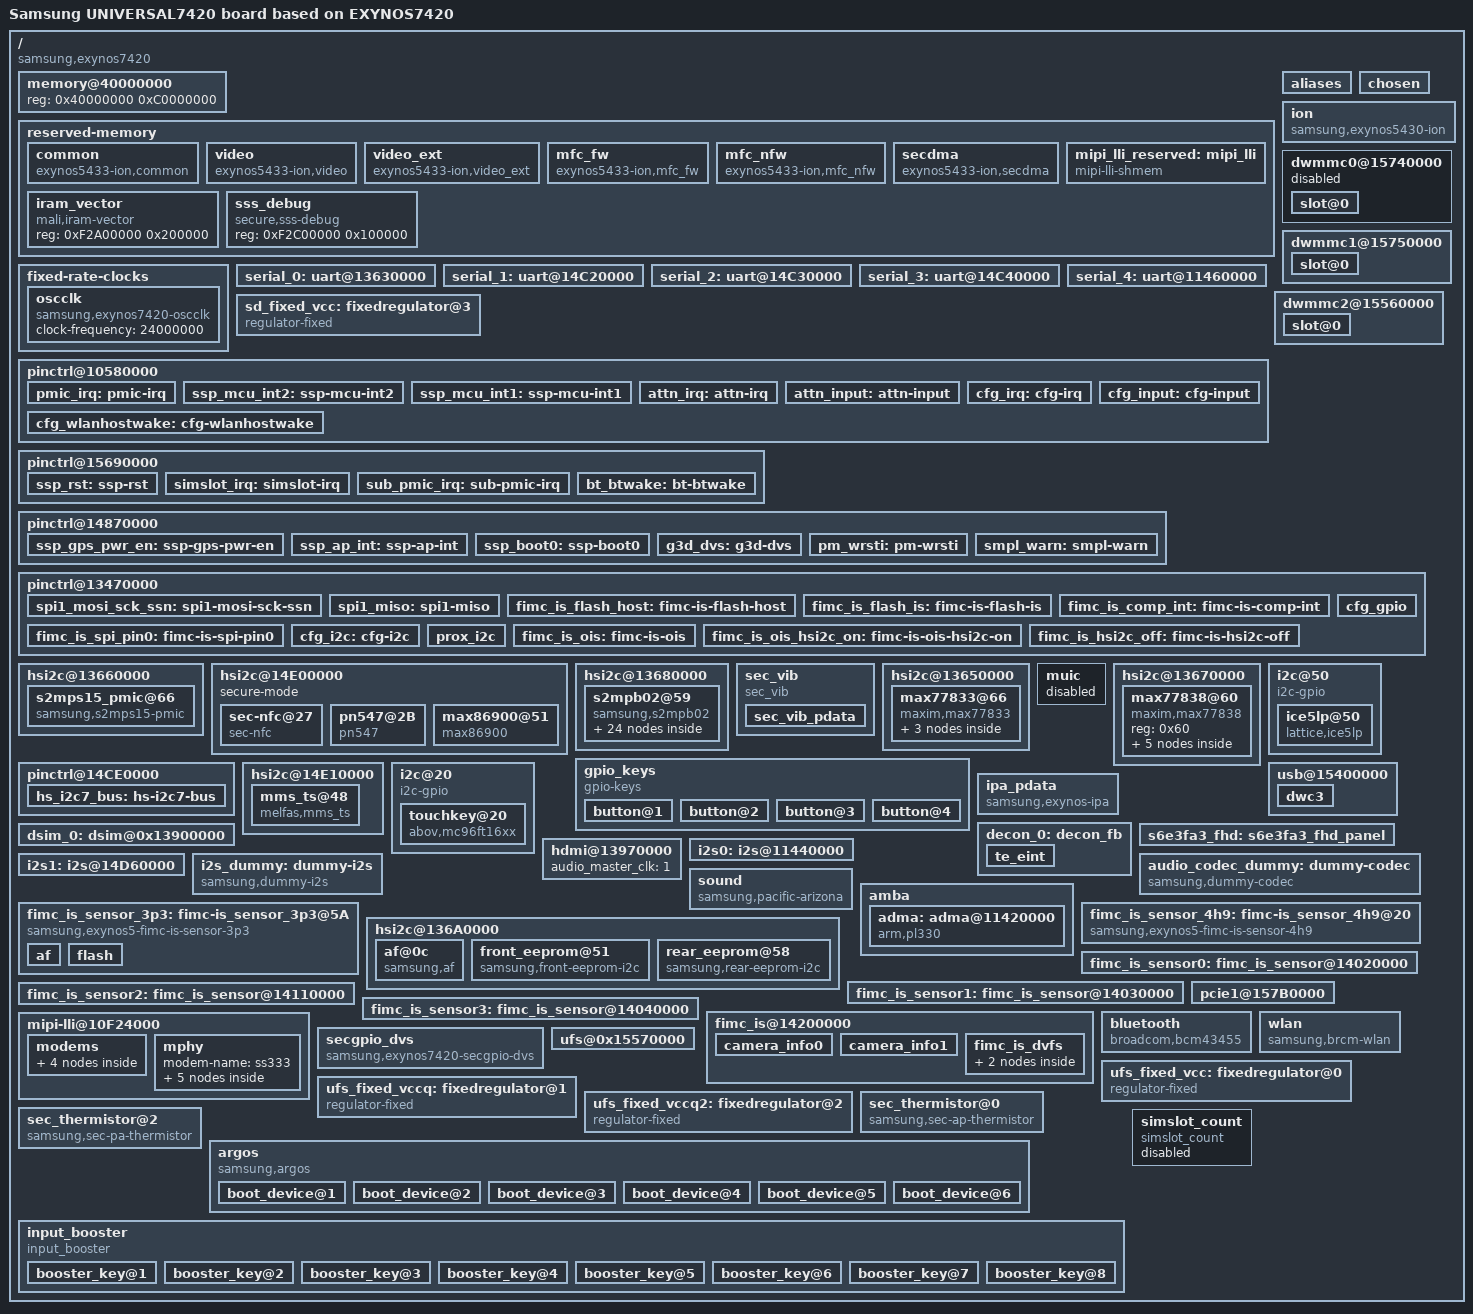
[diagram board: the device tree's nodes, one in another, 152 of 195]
/*
 * SAMSUNG UNIVERSAL7420 board device tree source
 *
 * Copyright (c) 2014 Samsung Electronics Co., Ltd.
 *		http://www.samsung.com
 *
 * This program is free software; you can redistribute it and/or modify
 * it under the terms of the GNU General Public License version 2 as
 * published by the Free Software Foundation.
*/

#include "exynos7420.dtsi"

/ {
	model = "Samsung UNIVERSAL7420 board based on EXYNOS7420";
	compatible = "samsung,exynos7420", "samsung,UNIVERSAL7420";

	memory@40000000 {
		device_type = "memory";
		reg = <0x40000000 0xC0000000>;
	};

	reserved-memory {
		#address-cells = <1>;
		#size-cells = <1>;
		ranges;

		common {
			compatible = "exynos5433-ion,common";
			size = <0x600000>;
			alignment = <0x1000>;
			id = <0>;
		};

		video {
			compatible = "exynos5433-ion,video";
			secure;
			reg = <0xE2A00000 0xE400000>;
			id = <11>;
			compat-id = <4 5 6 7>;
		};

		video_ext {
			compatible = "exynos5433-ion,video_ext";
			secure;
			reg = <0xF0E00000 0x600000>;
			id = <1>;
		};

		mfc_fw {
			compatible = "exynos5433-ion,mfc_fw";
			secure;
			reg = <0xE2800000 0x200000>;
			id = <8>;
		};

		mfc_nfw {
			compatible = "exynos5433-ion,mfc_nfw";
			reg = <0xE2600000 0x110000>;
			id = <12>;
		};

		secdma {
			compatible = "exynos5433-ion,secdma";
			size = <0x40000>;
			alignment = <0x40000>;
			id = <13>;
		};

		mipi_lli_reserved: mipi_lli {
			compatible = "mipi-lli-shmem";
			#memory-region-cells = <0>;
			size = <0x800000>;
			alignment = <0x800000>;
		};

		iram_vector {
			compatible = "mali,iram-vector";
			reg = <0xF2A00000 0x200000>;
		};

		sss_debug {
			compatible = "secure,sss-debug";
			reg = <0xF2C00000 0x100000>;
		};
	};

	aliases {
		spi0 = &spi_0;
		spi1 = &spi_1;
		spi2 = &spi_2;
		spi3 = &spi_3;
		spi4 = &spi_4;
		spi5 = &spi_5;
		spi6 = &spi_6;
		spi7 = &spi_7;
	};

	chosen {
		bootargs = "console=ttySAC1,115200n8 ess_setup=0x46000000";
		linux,initrd-start = <0x42000000>;
		linux,initrd-end = <0x420FFFFF>;
	};

	fixed-rate-clocks {
		oscclk {
			compatible = "samsung,exynos7420-oscclk";
			clock-frequency = <24000000>;
		};
	};

	ion {
		compatible = "samsung,exynos5430-ion";
	};

	serial_0: uart@13630000 {
		status = "okay";
	};

	serial_1: uart@14C20000 {
		/* Enable UART channel for debug port */
		status = "okay";
	};

	serial_2: uart@14C30000 {
		status = "okay";
	};

	serial_3: uart@14C40000 {
		status = "okay";
	};

	serial_4: uart@11460000 {
		pinctrl-0 = <&uart_bt_active &uart_bt_output_sleep &uart_bt_input_sleep>;
		status = "okay";
	};

	dwmmc0@15740000 {
		status = "disabled";
		num-slots = <1>;
		broken-cd;
		use-smu;
		fixed_volt;
		biu-clock-gate;
		clock-gate;
		enable-cclk-on-suspend;
		only_once_tune;
		use-fine-tuning;
		bypass-for-allpass;
		supports-highspeed;
		supports-hs200-mode;
		supports-ddr200-mode;
		enable-cache-control;
		use-enable-shift;
		qos_int_level = <400000>;
		ignore-phase=<( 1<<7 )>;
		desc-size = <3>;
		fifo-depth = <0x40>;
		card-detect-delay = <200>;
		data-timeout = <200>;
		samsung,dw-mshc-ciu-div = <3>;
		samsung,dw-mshc-sdr-timing = <3 0 2 1>;
		samsung,dw-mshc-ddr-timing = <3 0 3 2>;
		samsung,dw-mshc-hs200-timing = <3 0 3 1>;
		samsung,dw-mshc-ddr200-timing = <1 0 2 2>;
		samsung,dw-mshc-ddr200-delay-line = <118>;
		clk_pin = "gpr0-0";
		clk_addr = "15690000.pinctrl";
		clk_val = <0x4>;
		clk_str_num = <6>;
		num-ref-clks = <8>;
		ciu_clkin = <25 50 50 100 200 100 200 400>;
		pinctrl-names = "default";
		pinctrl-0 = <&sd0_clk &sd0_cmd &sd0_rdqs &sd0_bus1 &sd0_bus4 &sd0_bus8>;
		gpios = <&gph1 4 0>;
		slot@0 {
			reg = <0>;
			bus-width = <8>;
		};
	};

	dwmmc1@15750000 {
		status = "okay";
		num-slots = <1>;
		channel = <1>;
		fixed_volt;
		clock-gate;
		enable-cclk-on-suspend;
		caps-control;
		supports-highspeed;
		supports-sdr104-mode;
		not-allow-single-dma;
		fix-fmp-size-mismatch;
		keep-power-in-suspend;
		pm-ignore-notify;
		cd-type-external;
		cd-type = <2>;
		use-broken-voltage;
		use-fine-tuning;
		ignore-phase = <(1 << 7)>;
		fifo-depth = <0x40>;
		card-detect-delay = <200>;
		qos_int_level = <400000>;
		samsung,dw-mshc-ciu-div = <3>;
		samsung,dw-mshc-sdr-timing = <3 0 3 0>;
		samsung,dw-mshc-ddr-timing = <3 0 3 2>;
		clk_pin = "gpr2-0";
		clk_addr = "15690000.pinctrl";
		clk_val = <0x2>;
		clk_str_num = <6>;
		num-ref-clks = <8>;
		ciu_clkin = <25 50 50 100 200 100 200 400>;
		pinctrl-names = "default";
		pinctrl-0 = <&sd1_clk &sd1_cmd &sd1_bus1 &sd1_bus4>;
		//pinctrl-0 = <&sd1_clk &sd1_cmd &sd1_bus1 &sd1_bus4 &cfg_wlanen &cfg_wlanhostwake>; /* Set WLAN_EN configuration of power down mode */

		slot@0 {
			reg = <0>;
			bus-width = <4>;
		};
	};

	dwmmc2@15560000 {
		status = "okay";
		num-slots = <1>;
		caps-control;
		supports-highspeed;
		only_once_tune;
		supports-sdr50-mode;
		supports-sdr104-mode;
		enable-cclk-on-suspend;
		cd-type = <3>;
		bypass-smu;
		biu-clock-gate;
		clock-gate;
		use-fine-tuning;
		skip-init-mmc-scan;
		desc-size = <3>;
		fifo-depth = <0x40>;
		card-detect-delay = <200>;
		data-timeout = <200>;
		qos_int_level = <400000>;
		ignore-phase=<( 1<<7 )>;
		bypass-for-allpass;
		fix-fmp-size-mismatch;
		not-allow-single-dma;
		samsung,dw-mshc-ciu-div = <3>;
		samsung,dw-mshc-sdr-timing = <3 0 2 0>;
		samsung,dw-mshc-ddr-timing = <3 0 2 1>;
		samsung,dw-mshc-sdr50-timing = <3 0 3 2>;
		samsung,dw-mshc-sdr104-timing = <3 0 3 1>;
		clk_pin = "gpr4-0";
		clk_addr = "10E60000.pinctrl";
		clk_val = <0x2>;
		clk_str_num = <6>;
		num-ref-clks = <8>;
		ciu_clkin = <25 50 50 100 200 100 200 400>;
		pinctrl-names = "default";
		pinctrl-0 = <&sd2_clk &sd2_cmd &sd2_bus1 &sd2_bus4 &dwmmc2_cd_ext_irq>;
		gpio-controller;
		#gpio-cells = <2>;
		cd-gpio = <&gpa2 4 0xf>;
		sec-sd-slot-type = <3>;

		slot@0 {
			reg = <0>;
			bus-width = <4>;
			disable-wp;
		};
	};
        
	sd_fixed_vcc: fixedregulator@3 {
		compatible = "regulator-fixed";
		regulator-name = "vmmc";
		gpio = <&gpv6 2 1>;
		regulator-min-microvolt = <2800000>;
		regulator-max-microvolt = <2800000>;
		enable-active-high;
		regulator-initial-mode = <0>;
	};

	pinctrl@10580000 {
		pmic_irq: pmic-irq {
			samsung,pins = "gpa3-7";
			samsung,pin-pud = <3>;
			samsung,pin-drv = <3>;
		};

		ssp_mcu_int2: ssp-mcu-int2{
			samsung,pins = "gpa0-4";
			samsung,pin-function = <0>;
			samsung,pin-pud = <0>;
			samsung,pin-drv = <0>;
		};

		ssp_mcu_int1: ssp-mcu-int1 {
			samsung,pins = "gpa1-7";
			samsung,pin-function = <0>;
			samsung,pin-pud = <0>;
			samsung,pin-drv = <0>;
		};
	};

	pinctrl@15690000{
		ssp_rst: ssp-rst {
			samsung,pins = "gpr1-2";
			samsung,pin-function = <1>;
			samsung,pin-pud = <1>;
			samsung,pin-drv = <3>;
		};
	};

	pinctrl@14870000 {
		ssp_gps_pwr_en: ssp-gps-pwr-en {
			samsung,pins = "gpf4-7";
			samsung,pin-function = <1>;
			samsung,pin-pud = <0>;
			samsung,pin-drv = <3>;
		};

		ssp_ap_int: ssp-ap-int {
			samsung,pins = "gpf4-5";
			samsung,pin-function = <1>;
			samsung,pin-pud = <3>;
			samsung,pin-drv = <3>;
		};

		ssp_boot0: ssp-boot0 {
			samsung,pins = "gpf5-2";
			samsung,pin-function = <1>;
			samsung,pin-pud = <1>;
			samsung,pin-drv = <3>;
		};
	};

	pinctrl@13470000 {
		spi1_mosi_sck_ssn: spi1-mosi-sck-ssn {
			samsung,pins = "gpd6-2", "gpd6-3", "gpd6-5";
			samsung,pin-function = <2>;
			samsung,pin-pud = <3>;
			samsung,pin-drv = <3>;
		};

		spi1_miso: spi1-miso {
			samsung,pins = "gpd6-4";
			samsung,pin-function = <2>;
			samsung,pin-pud = <1>;
			samsung,pin-drv = <3>;
		};

		fimc_is_flash_host: fimc-is-flash-host {
			samsung,pins = "gpc0-2", "gpc0-3";
			samsung,pin-function = <1>;
			samsung,pin-pud = <1>;
			samsung,pin-drv = <0>;
		};

		fimc_is_flash_is: fimc-is-flash-is {
			samsung,pins = "gpc0-2", "gpc0-3";
			samsung,pin-function = <2>;
			samsung,pin-pud = <1>;
			samsung,pin-drv = <0>;
		};

		fimc_is_comp_int: fimc-is-comp-int {
			samsung,pins = "gpc0-0";
			samsung,pin-function = <0xf>;
			samsung,pin-pud = <0>;
			samsung,pin-drv = <0>;
		};

		fimc_is_spi_pin0: fimc-is-spi-pin0 {
			samsung,pins = "gpc3-3", "gpc3-2", "gpc3-0";
			samsung,pin-function = <0>;
			samsung,pin-pud = <1>;
			samsung,pin-drv = <3>;
		};
	};

	pinctrl@14870000 {
		g3d_dvs: g3d-dvs {
			samsung,pins = "gpg1-1";
			samsung,pin-function = <0x2>;
		};

		/* Warm reset information from AP */
		pm_wrsti: pm-wrsti {
			samsung,pins = "gpf3-0";
			samsung,pin-con-pdn = <3>;
		};

		/* smpl_warn */
		smpl_warn: smpl-warn {
			samsung,pins = "gpg1-0";
			samsung,pin-function = <0xf>;
			samsung,pin-pud = <0>;
		};
	};

	hsi2c@13660000 {
		status = "okay";
		samsung,hs-mode;
		clock-frequency = <2500000>;
		samsung,use-apm;

		s2mps15_pmic@66 {
			compatible = "samsung,s2mps15-pmic";
			reg = <0x66>;
			interrupts = <7 0 0>;
			interrupt-parent = <&gpa3>;
			pinctrl-names = "default";
			pinctrl-0 = <&pmic_irq &pm_wrsti &g3d_dvs &smpl_warn>;
			gpios = <&gpg1 0 0>, <&gpb0 4 0x2>, <&gpg1 1 0x1>;
			smpl_warn_en = <1>; /* 1 : enable , 0 : disable*/
			/* range of smpl_warn_vth */
			/* PMIC1 */
			/* 2100 : 2.3V, 2300 : 2.3V, 2500 : 2.5V, 2700 : 2.7V 2900 : 2.9V */
			/* 3100 : 3.0V, 3300 : 3.0V, 3500 : 3.0V */
			/* PMIC2 */
			/* 2100 : 2.1V, 2300 : 2.3V, 2500 : 2.5V, 2700 : 2.7V 2900 : 2.9V */
			/* 3100 : 3.1V, 3300 : 3.3V, 3500 : 3.5V */
			smpl_warn_vth = <2900>;
			smpl_warn_hys = <0x18>; /* LOwBat_Hys[4:3] 00(100mV)~11(400mV) */
			adc-on;
			buck_dvs_on;
			g3d_en = <1>; /* 1 : enable , 0 : disable */
			dvs_en = <1>; /* 1 : enable , 0 : disable */
			buck6en_pin = "gpb0-4";
			buck6en_addr = "13470000.pinctrl";
			/* RTC: wtsr/smpl */
			wtsr_en = <1>; /* enable */
			smpl_en = <1>; /* enable */
			wtsr_timer_val = <3>;	/* 1000ms */
			smpl_timer_val = <0>;	/* 100ms FIXME!!! */
			check_jigon = <0>; /* do not check jigon */
			/* RTC: If it's first boot, reset rtc to 1/1/2015 12:00:00(THU) */
			init_time,sec = <0>;
			init_time,min = <0>;
			init_time,hour = <12>;
			init_time,mday = <1>;
			init_time,mon = <0>;
			init_time,year = <115>;
			init_time,wday = <4>;
		};
	};

	hsi2c@14E00000 {
		status = "okay";
		secure-mode; /* flag for secure gpio recover function */
		sec-nfc@27 {
			compatible = "sec-nfc";
			reg = <0x27>;

			interrupts = <6 0 0>;
			interrupt-parent = <&gpa0>;

			sec-nfc,ven-gpio = <&gpf1 5 0>;
			sec-nfc,irq-gpio = <&gpa0 6 0>;
			sec-nfc,firm-gpio = <&gpf5 4 0>;
			sec-nfc,clk_req-gpio = <&gpa2 6 0xf>;
			sec-nfc,clk_use = <2>;
			pinctrl-names = "default";
			pinctrl-0 = <&nfc_n5_en &nfc_n5_firm>;
			clock-names = "sclk_isp_sensor1",
				"mout_sclk_isp_sensor1",
				"dout_sclk_isp_sensor1_a",
				"dout_sclk_isp_sensor1_b",
				"gate_top_cam1";
			clocks = <&clock 34>,
				<&clock 3067>,
				<&clock 4092>,
				<&clock 4093>,
				<&clock 2780>;
		};

		pn547@2B {
			compatible = "pn547";
			reg = <0x2B>;

			interrupts = <6 0 0>;
			interrupt-parent = <&gpa0>;

			pinctrl-names = "default";
			pinctrl-0 = <&nfc_pn547_en &nfc_n5_firm>;
			pn547,ven-gpio = <&gpf1 5 0>;
			pn547,firm-gpio = <&gpf5 4 0>;
			pn547,irq-gpio = <&gpa0 6 0>;
			pn547,clk_req-gpio = <&gpa2 6 0xf>;
			pn547,pwr_req = <&gpf5 1 0>;
			pn547,i2c_1p8 = "VDD20_1P8_AP";
		};

		max86900@51 {
			compatible = "max86900";
			reg = <0x51>;
			interrupt-parent = <&gpa1>;
			interrupts = <5 0 0>;
			pinctrl-names = "default", "sleep", "idle";
			pinctrl-0 = <&hrm_irq>;
			pinctrl-1 = <&hrm_irqsleep>;
			pinctrl-2 = <&hrm_irqidle>;
			max86900,hrm_int-gpio = <&gpa1 5 0>;
			max86900,vdd_1p8 = "HRM_VDD_1.8V";
			max86900,led_3p3 = "V_HRM_3.3V";
		};
	};

	hsi2c@13680000 {
		status = "okay";

		s2mpb02@59 {
			compatible = "samsung,s2mpb02";
			reg = <0x59>;

			s2mpb02,irq-gpio = <&gpr1 7 0>;
			pinctrl-names = "default";
			pinctrl-0 = <&sub_pmic_irq>;

			regulators {
				_buck1_reg: s2mpb02-buck1 {
					regulator-name = "VDD_1P6_DDR";
					regulator-min-microvolt = <1600000>;
					regulator-max-microvolt = <1600000>;
				};

				_buck2_reg: s2mpb02-buck2 {
					regulator-name = "VDDD_CORE_0.8V_COMP";
					regulator-min-microvolt = <650000>;
					regulator-max-microvolt = <850000>;
				};

				_ldo1_reg: s2mpb02-ldo1 {
					regulator-name = "VDDD_NORET_0.9V_COMP";
					regulator-min-microvolt = <900000>;
					regulator-max-microvolt = <900000>;
				};

				_ldo2_reg: s2mpb02-ldo2 {
					regulator-name = "VDDD_CORE_1.0V_COMP";
					regulator-min-microvolt = <1000000>;
					regulator-max-microvolt = <1000000>;
				};

				_ldo3_reg: s2mpb02-ldo3 {
					regulator-name = "VDDD_1.2V_CAM";
					regulator-min-microvolt = <1200000>;
					regulator-max-microvolt = <1200000>;
				};

				_ldo4_reg: s2mpb02-ldo4 {
					regulator-name = "VDDD_RET_1.0V_COMP";
					regulator-min-microvolt = <700000>;
					regulator-max-microvolt = <1000000>;
				};

				_ldo5_reg: s2mpb02-ldo5 {
					regulator-name = "VDDD_1.2V_VT";
					regulator-min-microvolt = <1050000>;
					regulator-max-microvolt = <1050000>;
				};

				_ldo6_reg: s2mpb02-ldo6 {
					regulator-name = "VDDIO_1.8V_VT";
					regulator-min-microvolt = <1800000>;
					regulator-max-microvolt = <1800000>;
				};

				_ldo7_reg: s2mpb02-ldo7 {
					regulator-name = "VDDIO_1.8V_CAM";
					regulator-min-microvolt = <1800000>;
					regulator-max-microvolt = <1800000>;
				};

				_ldo8_reg: s2mpb02-ldo8 {
					regulator-name = "VDDIO_1.8V_COMP";
					regulator-min-microvolt = <1800000>;
					regulator-max-microvolt = <1800000>;
				};

				_ldo9_reg: s2mpb02-ldo9 {
					regulator-name = "VDDA_1.8V_COMP";
					regulator-min-microvolt = <1800000>;
					regulator-max-microvolt = <1800000>;
				};

				_ldo10_reg: s2mpb02-ldo10 {
					regulator-name = "VCC_DISPLAY_1.8V";
					regulator-min-microvolt = <1800000>;
					regulator-max-microvolt = <1800000>;
				};

				_ldo11_reg: s2mpb02-ldo11 {
					regulator-name = "VDDA_2.9V_CAM";
					regulator-min-microvolt = <2950000>;
					regulator-max-microvolt = <2950000>;
				};

				_ldo12_reg: s2mpb02-ldo12 {
					regulator-name = "VDDAF_2.8V_CAM";
					regulator-min-microvolt = <2800000>;
					regulator-max-microvolt = <2800000>;
				};

				_ldo13_reg: s2mpb02-ldo13 {
					regulator-name = "VDDA_2.9V_VT";
					regulator-min-microvolt = <2900000>;
					regulator-max-microvolt = <2900000>;
				};

				_ldo14_reg: s2mpb02-ldo14 {
					regulator-name = "VDD_PROXY_3P3";
					regulator-min-microvolt = <3300000>;
					regulator-max-microvolt = <3300000>;
					regulator-boot-on;
					regulator-always-on;
				};

				_ldo15_reg: s2mpb02-ldo15 {
					regulator-name = "OIS_VDD_2.8V";
					regulator-min-microvolt = <2800000>;
					regulator-max-microvolt = <2800000>;
				};

				_ldo16_reg: s2mpb02-ldo16 {
					regulator-name = "vtouch_2.8v";
					regulator-min-microvolt = <2800000>;
					regulator-max-microvolt = <2800000>;
					regulator-boot-on;
				};

				_ldo17_reg: s2mpb02-ldo17 {
					regulator-name = "tsp_avdd";
					regulator-min-microvolt = <3300000>;
					regulator-max-microvolt = <3300000>;
				};

				_ldo18_reg: s2mpb02-ldo18 {
					regulator-name = "VDD_LCD_VCI_3P0";
					regulator-min-microvolt = <3000000>;
					regulator-max-microvolt = <3000000>;
				};
			};

			torch {
				status = "okay";
				leds1 {
					ledname = "leds-sec1";
					/* S2MPB02_FLASH_LED_1 */
					id = <0>;
					/* S2MPB02_FLASH_CURRENT */
					brightness = <0xA>;
					/* S2MPB02_FLASH_TIMEOUT */
					timeout = <0x3>;
				};

				leds2 {
					ledname = "torch-sec1";
					/* S2MPB02_TORCH_LED_1 */
					id = <1>;
					/* S2MPB02_TORCH_CURRENT */
					brightness = <0x9>;
					/* S2MPB02_TORCH_TIMEOUT */
					timeout = <0xF>;
					torch_table_enable = <1>;
					torch_table = <1 2 3 3 4 4 5 6 6 9>;
				};
			};
		};
	};

	sec_vib {
		compatible = "sec_vib";
		sec_vib_pdata {
			status = "okay";
			sec_vib,max_timeout = <10000>;
			sec_vib,ldo_type = <0>;		/* 0: pmic ldo, 1: external ldo */
			sec_vib,regulator = "VDD_MOTOR_3P3";
		};
	};

	hsi2c@13650000{
		status = "okay";

		max77833@66 {
			status = "okay";
			compatible = "maxim,max77833";
			reg = <0x66>;
			pinctrl-names = "default";
			pinctrl-0 = <&chg_irq &vibetonz_pwm>;
			max77833,irq-gpio = <&gpa1 4 &gpd2 5>;
			max77833,wakeup;

			regulators {
				ESAFEOUT1 {
					regulator-compatible = "safeout1";
					regulator-name = "safeout1_range";
					regulator-min-microvolt = <3300000>;
					regulator-max-microvolt = <4900000>;
					regulator-boot-on;
				};

				ESAFEOUT2 {
					regulator-compatible = "safeout2";
					regulator-name = "safeout2_range";
					regulator-min-microvolt = <3300000>;
					regulator-max-microvolt = <4900000>;
				};
			};
		};
	};

	muic {
		status = "disabled";
		muic,support-list = "TA","USB","Jig UART Off","Jig UART Off + VB","Jig UART On",
				"Jig USB On","CDP","Unofficial ID","OTG",
				"Unofficial TA","Undefined Charging",
				"AFC charger","QC charger","Deskdock","Deskdock + TA",
				"Unofficial ID + TA","Unofficial ID + CDP","Unofficial ID + USB",
				"Timeout Open Charging","Unsupported ID + VB";
	};

	hsi2c@13670000 {
		status = "okay";

		max77838@60 {
			compatible = "maxim,max77838";
			reg = <0x60>;

			regulators {
				__ldo1_reg: LDO1 {
					regulator-name = "VCC_DISPLAY_1.8V";
					regulator-min-microvolt = <1800000>;
					regulator-max-microvolt = <1800000>;
					regulator-boot-on;
				};

				__ldo2_reg: LDO2 {
					regulator-name = "tsp_io";
					regulator-min-microvolt = <1850000>;
					regulator-max-microvolt = <1850000>;
				};

				__ldo3_reg: LDO3 {
					regulator-name = "VCC_3.0V_LCD";
					regulator-min-microvolt = <3000000>;
					regulator-max-microvolt = <3000000>;
					regulator-boot-on;
				};

				__ldo4_reg: LDO4 {
					regulator-name = "tsp_avdd";
					regulator-min-microvolt = <3300000>;
					regulator-max-microvolt = <3300000>;
				};
			};
		};
	};

	i2c@50 {
		compatible = "i2c-gpio";
		gpios = <&gpr2 3 0 /* sda */
			&gpr2 4 0 /* scl */
			>;
		i2c-gpio,delay-us = <2>;
		#address-cells = <1>;
		#size-cells = <0>;
		status = "okay";
		ice5lp@50 {
			compatible = "lattice,ice5lp";
			reg = <0x50>;
			ice5lp,creset_b = <&gpr2 1 0>;
			ice5lp,cdone = <&gpf5 6 0>;
			ice5lp,irda_irq = <&gpr2 2 0>;
			ice5lp,spi_si_sda = <&gpr2 3 0>;
			ice5lp,spi_clk_scl = <&gpr2 4 0>;
			ice5lp,spi_en_rstn = <&gpr2 0 0>;
			irled,power_type = "LDO";
			irled,ldo = <&gpf1 2 0>;
			clocks = <&clock 4300>;
			clock-names = "clk_out";
		};
	};

	pinctrl@10580000 {
		attn_irq: attn-irq {
			samsung,pins = "gpa1-6";
			samsung,pin-function = <0xf>;
			samsung,pin-pud = <0>;
			samsung,pin-drv = <0>;
		};
		attn_input: attn-input {
			samsung,pins = "gpa1-6";
			samsung,pin-function = <0>;
			samsung,pin-pud = <1>;
			samsung,pin-drv = <0>;
		};
	};

	gpio_keys {
		compatible = "gpio-keys";
		#address-cells = <1>;
		#size-cells = <0>;
		pinctrl-names = "default";
		button@1 {
			label = "gpio-keys: KEY_POWER";
			interrupts = <2 0 0>;
			interrupt-parent = <&gpa2>;
			linux,code = <116>;
			gpios = <&gpa2 2 0xf>;
			gpio-key,wakeup = <1>;
		};
		button@2 {
			label = "gpio-keys: KEY_VOLUMEDOWN";
			interrupts = <3 0 0>;
			interrupt-parent = <&gpa0>;
			linux,code = <114>;
			gpios = <&gpa0 3 0xf>;
		};
		button@3 {
			label = "gpio-keys: KEY_VOLUMEUP";
			interrupts = <2 0 0>;
			interrupt-parent = <&gpa0>;
			linux,code = <115>;
			gpios = <&gpa0 2 0xf>;
		};
		button@4 {
			label = "gpio-keys: KEY_HOMEPAGE";
			interrupts = <5 0 0>;
			interrupt-parent = <&gpa0>;
			linux,code = <172>;
			gpios = <&gpa0 5 0xf>;
			gpio-key,wakeup = <1>;
		};
	};

	pinctrl@14CE0000 {
		hs_i2c7_bus: hs-i2c7-bus {
			samsung,pins = "gpj1-1", "gpj1-0";
			samsung,pin-pud = <0>;
			samsung,pin-drv = <0>;
			samsung,pin-con-pdn = <2>;
			samsung,pin-pud-pdn = <1>;
		};
	};

	hsi2c@14E10000 {
		/delete-property/ pinctrl-names;
		/delete-property/ pinctrl-0;
		/delete-property/ gpio_sda;
		/delete-property/ gpio_scl;
		status = "okay";
		secure-mode; /* flag for secure gpio recover function */
		clock-frequency = <350000>;
		t-data-su = <2>;
		mms_ts@48 {
			compatible = "melfas,mms_ts";
			reg = <0x48>;
			pinctrl-names = "on_state", "off_state";
			pinctrl-0 = <&attn_irq>;
			pinctrl-1 = <&attn_input>;
			melfas,vdd_en = "tsp_avdd";
			melfas,io_en = "tsp_io";
			melfas,irq-gpio = <&gpa1 6 0>;
			melfas,scl-gpio = <&gpj1 1 0>;
			melfas,sda-gpio = <&gpj1 0 0>;
			melfas,max_x = <2160>;
			melfas,max_y = <3840>;
			melfas,support_lpm = "true";
			melfas,fw_name = "tsp_melfas/mms449_a8x.fw";
		};
	};

	pinctrl@13470000 {
		/* touchkey i2c*/
		cfg_i2c: cfg-i2c {
			samsung,pins = "gpd1-3", "gpd1-2";
			samsung,pin-function = <3>;
			samsung,pin-pud = <0>;
			samsung,pin-drv = <0>;
		};
		cfg_gpio: cfg_gpio {
			samsung,pins = "gpd1-3", "gpd1-2";
			samsung,pin-function = <0>;
			samsung,pin-pud = <0>;
			samsung,pin-drv = <0>;
		};
		prox_i2c: prox_i2c {
			samsung,pins = "gpg3-3", "gpg3-2";
			samsung,pin-function = <0>;
			samsung,pin-pud = <0>;
			samsung,pin-drv = <0>;
		};
	};

	pinctrl@10580000 {
		/* touchkey interrupt*/
		cfg_irq: cfg-irq {
			samsung,pins = "gpa0-0";
			samsung,pin-function = <0xf>;
			samsung,pin-pud = <0>;
			samsung,pin-drv = <0>;
		};
		cfg_input: cfg-input {
			samsung,pins = "gpa0-0";
			samsung,pin-function = <0>;
			samsung,pin-pud = <0>;
			samsung,pin-drv = <0>;
		};
	};

	i2c@20{
		compatible = "i2c-gpio";
		gpios = <&gpd1 2 0 /* sda */
				&gpd1 3 0 /* scl */
				>;
		i2c-gpio,delay-us = <2>;
		#address-cells = <1>;
		#size-cells = <0>;
		status = "okay";
		pinctrl-names = "default","on_i2c","off_i2c";
		pinctrl-0 = <&cfg_i2c>;
		pinctrl-1 = <&cfg_i2c>;
		pinctrl-2 = <&cfg_gpio>;
		touchkey@20 {
			compatible = "abov,mc96ft16xx";
			pinctrl-names = "on_irq","off_irq";
			pinctrl-0 = <&cfg_irq>;
			pinctrl-1 = <&cfg_input>;
			reg = <0x20>;
			interrupts = <0 0 0>;
			interrupt-parent = <&gpa0>;
			abov,sda-gpio = <&gpd1 2 0>;
			abov,scl-gpio = <&gpd1 3 0>;
			abov,irq-gpio = <&gpa0 0 1>;
			/* abov,sub-det = <&gpa3 0 0>; */
			abov,boot-on-ldo = "true";
			abov,fw_path = "abov/abov_a8x.fw";
		};
	};

	usb@15400000 {
		status = "okay";

		dwc3 {
			maximum-speed = "high-speed";
			dr_mode = "otg";
			adj-sof-accuracy;
		};
	};

	ipa_pdata {
		compatible = "samsung,exynos-ipa";

		control_temp = <90>;
		temp_threshold = <10>;
		enabled = <1>;
		tdp = <3500>;
		boost = <1>;
		ros_power = <500>;
		little_weight = <1024>;
		big_weight = <256>;
		gpu_weight = <256>;
		little_max_power = <1000>;
		big_max_power = <6552>;
		gpu_max_power = <3110>;
		hotplug_out_threshold = <10>;
		hotplug_in_threshold = <0>;
		enable_ctlr = <1>;
		ctlr.mult = <2>;
		ctlr.k_i = <1>;
		ctlr.k_d = <0>;
		ctlr.feed_forward = <1>;
		ctlr.integral_reset_value = <0>;
		ctlr.integral_cutoff = <0>;
		ctlr.integral_reset_threshold = <5>;
	};

	decon_0: decon_fb {
		/* EINT for TE */
		gpios = <&gpg0 0 0xf>;
		gpio_err = <&gpr1 6 0>;
		/* gpio_det = <&gpr1 1 0>; */
		gpio_pcd = <&gpa1 2 0>;
		te_eint {
			reg = <0x13470A34 0x4>, <0x13470934 0x4>;
			te_pend_mask = <0x00000001>;
		};
	};

	dsim_0: dsim@0x13900000 {
		gpios = <&gpr1 0 0x1>;
		regulator_30V = "VDD_1P6_DDR";
		regulator_18V = "VCC_DISPLAY_1.8V";
		regulator_16V = "VDD_LCD_VCI_3P0";
		lcd_info = <&s6e3fa3_fhd>;
	};

	s6e3fa3_fhd: s6e3fa3_fhd_panel {
		mode = <2>;
		resolution = <1080 1920>;
		size = <71 126>;
		timing,refresh = <60>;
		timing,h-porch = <1 1 1>;
		timing,v-porch = <15 1 1>;
		timing,dsi-hs-clk = <916>;
		timing,dsi-escape-clk = <16>;
		mic = <0>;
		type_of_ddi = <0>;
	};

	hdmi@13970000 {
		/* all bit clock supports: 1, not support: 0 */
		audio_master_clk = <1>;
	};

	i2s0: i2s@11440000 {
		/*samsung,supports-esa-dma;*/
		/*samsung,supports-sec-compr;*/
		status = "okay";
	};

	i2s1: i2s@14D60000 {
		status = "okay";
	};

	audio_codec_dummy: dummy-codec {
		compatible = "samsung,dummy-codec";
		status = "okay";
	};

	i2s_dummy: dummy-i2s {
		compatible = "samsung,dummy-i2s";
		status = "okay";
	};

	sound {
		compatible = "samsung,pacific-arizona";
		samsung,audio-cpu = <
			&i2s0	/* primary */
			&i2s_dummy
			&i2s_dummy
			&i2s0			/* secondary */
			&i2s_dummy		/* voice wakeup */
			&i2s_dummy		/* dsp trace */
			&eax			/* eax0 ~ 3 */
			&eax
			&eax
			&eax
		>;
		samsung,audio-codec = <
			&audio_codec
			&audio_codec
			&audio_codec
			&audio_codec
			&audio_codec_dummy
			&audio_codec_dummy
			&audio_codec
			&audio_codec
			&audio_codec
			&audio_codec
		>;
		clocks = <&clock 45>;
		clock-names = "mclk";
		status = "okay";
	};

	amba {
		adma: adma@11420000 {
			compatible = "arm,pl330", "arm,primecell";
			reg = <0x11420000 0x1000>;
			interrupts = <0 97 0>;
			clocks = <&clock 400>;
			clock-names = "apb_pclk";
			#dma-cells = <1>;
			#dma-channels = <8>;
			#dma-requests = <16>;
			#dma-mcode-addr = <0x03047000>;
			samsung,lpass-subip;
			status = "ok";
		};
	};

	fimc_is_sensor_3p3: fimc-is_sensor_3p3@5A {
		compatible = "samsung,exynos5-fimc-is-sensor-3p3";

		pinctrl-names = "pin0", "pin1", "pin2";
		pinctrl-0 = <>;
		pinctrl-1 = <&fimc_is_flash_is &fimc_is_mclk0_out &fimc_is_mclk1_out &fimc_is_i2c0 &fimc_is_i2c2>;
		pinctrl-2 = <&fimc_is_flash_is &fimc_is_mclk0_fn &fimc_is_mclk1_fn &fimc_is_i2c0 &fimc_is_i2c2>;

		position = <0>;	/* Rear:0. Front:1 */
		id = <0>; /* bns_id */
		mclk_ch = <0>;
		sensor_i2c_ch = <0>; /* I2C 0 */
		sensor_i2c_addr = <0x5A>;

		gpio_mclk = <&gpd7 0 0x1>;
		gpio_reset = <&gpc0 5 0x1>; /* sensor reset */
		status = "okay";

		af {
			product_name = <13>; /* DW9807 */
			i2c_addr = <0x18>;
			i2c_ch = <2>; /* I2C 2 */
		};

		flash {
			product_name = <3>; /* S2MPB02 */
			flash_first_gpio = <2>;
			flash_second_gpio = <3>;
		};
	};

	hsi2c@136A0000 {
		status = "okay";
		clock-frequency = <400000>;
		pinctrl-names = "default","on_i2c","off_i2c";
		pinctrl-0 = <&fimc_is_hsi2c_off>;
		pinctrl-1 = <&fimc_is_ois_hsi2c_on>;
		pinctrl-2 = <&fimc_is_hsi2c_off>;

		af@0c{
			compatible = "samsung,af";
			reg = <0x0c>;
			use_i2c_pinctrl;
			fimc_is_af_pinname = "13470000.pinctrl";
			fimc_is_af_sda = "gpc2-4";
			fimc_is_af_scl = "gpc2-5";
			pinfunc_on = <0>;
			pinfunc_off = <2>;
		};

		front_eeprom@51 {
			compatible = "samsung,front-eeprom-i2c";
			reg = <0x51>;
			use_i2c_pinctrl;
			fimc_is_front_eeprom_pinname = "13470000.pinctrl";
			fimc_is_front_eeprom_sda = "gpb2-4";
			fimc_is_front_eeprom_scl = "gpb2-5";
			pinfunc_on = <0>;
			pinfunc_off = <2>;
		};

		rear_eeprom@58 {
			compatible = "samsung,rear-eeprom-i2c";
			reg = <0x58>;
			use_i2c_pinctrl;
			fimc_is_rear_eeprom_pinname = "13470000.pinctrl";
			fimc_is_rear_eeprom_sda = "gpc2-4";
			fimc_is_rear_eeprom_scl = "gpc2-5";
			pinfunc_on = <0>;
			pinfunc_off = <2>;
		};
	};

	fimc_is_sensor_4h9: fimc-is_sensor_4h9@20 {
		compatible = "samsung,exynos5-fimc-is-sensor-4h9";

		pinctrl-names = "pin0", "pin1", "pin2";
		pinctrl-0 = <>;
		pinctrl-1 = <&fimc_is_mclk2_out &fimc_is_i2c1>;
		pinctrl-2 = <&fimc_is_mclk2_fn &fimc_is_i2c1>;

		position = <1>;	/* Rear:0. Front:1 */
		id = <1>; /* bns_id */
		mclk_ch = <2>;
		sensor_i2c_ch = <1>;
		sensor_i2c_addr = <0x20>;

		gpio_mclk = <&gpd7 2 0x1>;
		gpio_reset = <&gpc0 4 0x1>;
		gpio_standby = <&gpc0 6 0x1>;
		status = "okay";
		rom_power_seq_ver = <1>;
	};

	fimc_is_sensor0: fimc_is_sensor@14020000 {
		scenario = <0>;	/* Normal, Vision, OIS etc */
		id = <0>; /* bns_id */
		csi_ch = <0>;
		flite_ch = <0>;
		is_bns = <1>;
		status = "okay";
	};

	fimc_is_sensor1: fimc_is_sensor@14030000 {
		scenario = <0>;	/* Normal, Vision, OIS etc */
		id = <1>; /* bns_id */
		csi_ch = <1>;
		flite_ch = <1>;
		is_bns = <0>;
		status = "okay";
	};

	fimc_is_sensor2: fimc_is_sensor@14110000 {
		scenario = <0>;	/* Normal, Vision, OIS etc */
		id = <2>; /* bns_id */
		csi_ch = <2>;
		flite_ch = <2>;
		is_bns = <1>;
		status = "okay";
	};

	fimc_is_sensor3: fimc_is_sensor@14040000 {
		scenario = <0>;	/* Normal, Vision, OIS etc */
		id = <3>; /* bns_id */
		csi_ch = <3>;
		flite_ch = <3>;
		is_bns = <0>;
		status = "okay";
	};

	fimc_is@14200000 {
		rear_sensor_id = <23>;
		front_sensor_id = <35>;
		use_module_check;
		use_ois_hsi2c;
		check_sensor_vendor;

		pinctrl-names = "default", "release";
		pinctrl-0 = <&fimc_is_flash_is &fimc_is_mclk0_out &fimc_is_mclk1_out &fimc_is_mclk2_out>;
		pinctrl-1 = <>;

		total_camera_num = <2>;
		camera_info0 {				// 0 : rear
			isp = <0>;			/* 0 : INT , 1 : EXT , 2 : SOC */
			cal_memory = <2>;		/* 0 : N , 1 : FROM , 2 : EEPROM , 3 : OTP  */
			read_version = <0>;		/* 0 : SYSFS , 1 : CAMON */
			core_voltage = <0>;		/* 0 : N , 1 : Y  */
			upgrade = <0>;		/* 0 : N , 1 : SYSFS , 2 : CAMON */
			fw_write = <0>;		/* 0 : N,  1 : OS, 2 : SD, 3 : ALL */
			fw_dump = <0>;		/* 0 : N , 1 : Y  */
			companion = <0>;		/* 0 : N , 1 : Y  */
			ois = <0>;			/* 0 : N , 1 : Y  */
		};
		camera_info1 {				// 1 : front
			isp = <0>;			/* 0 : INT , 1 : EXT , 2 : SOC */
			cal_memory = <2>;		/* 0 : N , 1 : FROM , 2 : EEPROM , 3 : OTP  */
			read_version = <0>;		/* 0 : SYSFS , 1 : CAMON */
			core_voltage = <0>;		/* 0 : N , 1 : Y  */
			upgrade = <0>;		/* 0 : N , 1 : SYSFS , 2 : CAMON */
			fw_write = <0>;		/* 0 : N,  1 : OS, 2 : SD, 3 : ALL */
			fw_dump = <0>;		/* 0 : N , 1 : Y  */
			companion = <0>;		/* 0 : N , 1 : Y  */
			ois = <0>;			/* 0 : N , 1 : Y  */
		};

		#define DVFS_INT_L0 560000
		#define DVFS_INT_L1 550000
		#define DVFS_INT_L2 540000
		#define DVFS_INT_L3 530000
		#define DVFS_INT_L4 520000
		#define DVFS_INT_L5 510000
		#define DVFS_INT_L6 500000

		#define DVFS_CAM_L0 540000
		#define DVFS_CAM_L1 530000
		#define DVFS_CAM_L2 520000
		#define DVFS_CAM_L3 510000
		#define DVFS_CAM_L4 500000

		#define DVFS_MIF_L0 1552000
		#define DVFS_MIF_L1 1456000
		#define DVFS_MIF_L2 1264000
		#define DVFS_MIF_L3 1068000
		#define DVFS_MIF_L4 828000
		#define DVFS_MIF_L5 632000

		fimc_is_dvfs {
			/* purebayer version */
			table1 {
				desc = "Pure bayer Version";

				default_int = <DVFS_INT_L0>;
				default_cam = <DVFS_CAM_L0>;
				default_mif = <DVFS_MIF_L1>;
				default_i2c = <0>;

				front_preview_int = <DVFS_INT_L1>;
				front_preview_cam = <DVFS_CAM_L0>;
				front_preview_mif = <DVFS_MIF_L4>;
				front_preview_i2c = <0>;

				front_capture_int = <DVFS_INT_L1>;
				front_capture_cam = <DVFS_CAM_L0>;
				front_capture_mif = <DVFS_MIF_L4>;
				front_capture_i2c = <0>;

				front_video_int = <DVFS_INT_L1>;
				front_video_cam = <DVFS_CAM_L0>;
				front_video_mif = <DVFS_MIF_L4>;
				front_video_i2c = <0>;

				front_video_whd_int = <DVFS_INT_L1>;
				front_video_whd_cam = <DVFS_CAM_L0>;
				front_video_whd_mif = <DVFS_MIF_L4>;
				front_video_whd_i2c = <0>;

				front_video_capture_int = <DVFS_INT_L1>;
				front_video_capture_cam = <DVFS_CAM_L0>;
				front_video_capture_mif = <DVFS_MIF_L4>;
				front_video_capture_i2c = <0>;

				front_video_whd_capture_int = <DVFS_INT_L1>;
				front_video_whd_capture_cam = <DVFS_CAM_L0>;
				front_video_whd_capture_mif = <DVFS_MIF_L4>;
				front_video_whd_capture_i2c = <0>;

				front_vt1_int = <DVFS_INT_L6>;
				front_vt1_cam = <DVFS_CAM_L4>;
				front_vt1_mif = <DVFS_MIF_L4>;
				front_vt1_i2c = <0>;

				front_vt2_int = <DVFS_INT_L6>;
				front_vt2_cam = <DVFS_CAM_L4>;
				front_vt2_mif = <DVFS_MIF_L4>;
				front_vt2_i2c = <0>;

				front_companion_preview_int = <DVFS_INT_L3>;
				front_companion_preview_cam = <DVFS_CAM_L4>;
				front_companion_preview_mif = <DVFS_MIF_L4>;
				front_companion_preview_i2c = <0>;

				front_companion_capture_int = <DVFS_INT_L3>;
				front_companion_capture_cam = <DVFS_CAM_L4>;
				front_companion_capture_mif = <DVFS_MIF_L4>;
				front_companion_capture_i2c = <0>;

				front_companion_video_int = <DVFS_INT_L3>;
				front_companion_video_cam = <DVFS_CAM_L4>;
				front_companion_video_mif = <DVFS_MIF_L4>;
				front_companion_video_i2c = <0>;

				front_companion_video_whd_int = <DVFS_INT_L3>;
				front_companion_video_whd_cam = <DVFS_CAM_L4>;
				front_companion_video_whd_mif = <DVFS_MIF_L4>;
				front_companion_video_whd_i2c = <0>;

				front_companion_video_capture_int = <DVFS_INT_L3>;
				front_companion_video_capture_cam = <DVFS_CAM_L4>;
				front_companion_video_capture_mif = <DVFS_MIF_L4>;
				front_companion_video_capture_i2c = <0>;

				front_companion_video_whd_capture_int = <DVFS_INT_L3>;
				front_companion_video_whd_capture_cam = <DVFS_CAM_L4>;
				front_companion_video_whd_capture_mif = <DVFS_MIF_L4>;
				front_companion_video_whd_capture_i2c = <0>;

				rear_preview_fhd_int = <DVFS_INT_L1>;
				rear_preview_fhd_cam = <DVFS_CAM_L0>;
				rear_preview_fhd_mif = <DVFS_MIF_L4>;
				rear_preview_fhd_i2c = <0>;

				rear_preview_whd_int = <DVFS_INT_L1>;
				rear_preview_whd_cam = <DVFS_CAM_L0>;
				rear_preview_whd_mif = <DVFS_MIF_L4>;
				rear_preview_whd_i2c = <0>;

				rear_preview_uhd_int = <DVFS_INT_L0>;
				rear_preview_uhd_cam = <DVFS_CAM_L0>;
				rear_preview_uhd_mif = <DVFS_MIF_L4>;
				rear_preview_uhd_i2c = <0>;

				rear_capture_int = <DVFS_INT_L0>;
				rear_capture_cam = <DVFS_CAM_L0>;
				rear_capture_mif = <DVFS_MIF_L1>;
				rear_capture_i2c = <0>;

				rear_video_fhd_int = <DVFS_INT_L2>;
				rear_video_fhd_cam = <DVFS_CAM_L0>;
				rear_video_fhd_mif = <DVFS_MIF_L4>;
				rear_video_fhd_i2c = <0>;

				rear_video_whd_int = <DVFS_INT_L2>;
				rear_video_whd_cam = <DVFS_CAM_L0>;
				rear_video_whd_mif = <DVFS_MIF_L4>;
				rear_video_whd_i2c = <0>;

				rear_video_uhd_int = <DVFS_INT_L0>;
				rear_video_uhd_cam = <DVFS_CAM_L0>;
				rear_video_uhd_mif = <DVFS_MIF_L4>;
				rear_video_uhd_i2c = <0>;

				rear_video_fhd_capture_int = <DVFS_INT_L0>;
				rear_video_fhd_capture_cam = <DVFS_CAM_L0>;
				rear_video_fhd_capture_mif = <DVFS_MIF_L1>;
				rear_video_fhd_capture_i2c = <0>;

				rear_video_whd_capture_int = <DVFS_INT_L0>;
				rear_video_whd_capture_cam = <DVFS_CAM_L0>;
				rear_video_whd_capture_mif = <DVFS_MIF_L1>;
				rear_video_whd_capture_i2c = <0>;

				rear_video_uhd_capture_int = <DVFS_INT_L0>;
				rear_video_uhd_capture_cam = <DVFS_CAM_L0>;
				rear_video_uhd_capture_mif = <DVFS_MIF_L1>;
				rear_video_uhd_capture_i2c = <0>;

				dual_preview_int = <DVFS_INT_L0>;
				dual_preview_cam = <DVFS_CAM_L0>;
				dual_preview_mif = <DVFS_MIF_L1>;
				dual_preview_i2c = <0>;

				dual_capture_int = <DVFS_INT_L0>;
				dual_capture_cam = <DVFS_CAM_L0>;
				dual_capture_mif = <DVFS_MIF_L1>;
				dual_capture_i2c = <0>;

				dual_video_int = <DVFS_INT_L0>;
				dual_video_cam = <DVFS_CAM_L0>;
				dual_video_mif = <DVFS_MIF_L1>;
				dual_video_i2c = <0>;

				dual_video_capture_int = <DVFS_INT_L0>;
				dual_video_capture_cam = <DVFS_CAM_L0>;
				dual_video_capture_mif = <DVFS_MIF_L1>;
				dual_video_capture_i2c = <0>;

				preview_high_speed_fps_int = <DVFS_INT_L1>;
				preview_high_speed_fps_cam = <DVFS_CAM_L0>;
				preview_high_speed_fps_mif = <DVFS_MIF_L1>;
				preview_high_speed_fps_i2c = <0>;

				video_high_speed_60fps_int = <DVFS_INT_L1>;
				video_high_speed_60fps_cam = <DVFS_CAM_L3>;
				video_high_speed_60fps_mif = <DVFS_MIF_L4>;
				video_high_speed_60fps_i2c = <0>;

				video_high_speed_120fps_int = <DVFS_INT_L1>;
				video_high_speed_120fps_cam = <DVFS_CAM_L3>;
				video_high_speed_120fps_mif = <DVFS_MIF_L1>;
				video_high_speed_120fps_i2c = <0>;

				video_high_speed_240fps_int = <DVFS_INT_L0>;
				video_high_speed_240fps_cam = <DVFS_CAM_L0>;
				video_high_speed_240fps_mif = <DVFS_MIF_L0>;
				video_high_speed_240fps_i2c = <0>;

				max_int = <DVFS_INT_L0>;
				max_cam = <DVFS_CAM_L0>;
				max_mif = <DVFS_MIF_L1>;
				max_i2c = <0>;
			};

			table2 {
				desc = "processed bayer 16MP version";

				default_int = <DVFS_INT_L4>;
				default_cam = <DVFS_CAM_L1>;
				default_mif = <DVFS_MIF_L4>;
				default_i2c = <0>;

				front_preview_int = <DVFS_INT_L3>;
				front_preview_cam = <DVFS_CAM_L0>;
				front_preview_mif = <DVFS_MIF_L4>;
				front_preview_i2c = <0>;

				front_capture_int = <DVFS_INT_L3>;
				front_capture_cam = <DVFS_CAM_L0>;
				front_capture_mif = <DVFS_MIF_L4>;
				front_capture_i2c = <0>;

				front_video_int = <DVFS_INT_L3>;
				front_video_cam = <DVFS_CAM_L0>;
				front_video_mif = <DVFS_MIF_L4>;
				front_video_i2c = <0>;

				front_video_whd_int = <DVFS_INT_L3>;
				front_video_whd_cam = <DVFS_CAM_L0>;
				front_video_whd_mif = <DVFS_MIF_L4>;
				front_video_whd_i2c = <0>;

				front_video_capture_int = <DVFS_INT_L3>;
				front_video_capture_cam = <DVFS_CAM_L0>;
				front_video_capture_mif = <DVFS_MIF_L4>;
				front_video_capture_i2c = <0>;

				front_video_whd_capture_int = <DVFS_INT_L3>;
				front_video_whd_capture_cam = <DVFS_CAM_L0>;
				front_video_whd_capture_mif = <DVFS_MIF_L4>;
				front_video_whd_capture_i2c = <0>;

				front_vt1_int = <DVFS_INT_L6>;
				front_vt1_cam = <DVFS_CAM_L4>;
				front_vt1_mif = <DVFS_MIF_L4>;
				front_vt1_i2c = <0>;

				front_vt2_int = <DVFS_INT_L6>;
				front_vt2_cam = <DVFS_CAM_L4>;
				front_vt2_mif = <DVFS_MIF_L4>;
				front_vt2_i2c = <0>;

				front_companion_preview_int = <DVFS_INT_L3>;
				front_companion_preview_cam = <DVFS_CAM_L4>;
				front_companion_preview_mif = <DVFS_MIF_L4>;
				front_companion_preview_i2c = <0>;

				front_companion_capture_int = <DVFS_INT_L3>;
				front_companion_capture_cam = <DVFS_CAM_L4>;
				front_companion_capture_mif = <DVFS_MIF_L4>;
				front_companion_capture_i2c = <0>;

				front_companion_video_int = <DVFS_INT_L3>;
				front_companion_video_cam = <DVFS_CAM_L4>;
				front_companion_video_mif = <DVFS_MIF_L4>;
				front_companion_video_i2c = <0>;

				front_companion_video_whd_int = <DVFS_INT_L3>;
				front_companion_video_whd_cam = <DVFS_CAM_L4>;
				front_companion_video_whd_mif = <DVFS_MIF_L4>;
				front_companion_video_whd_i2c = <0>;

				front_companion_video_capture_int = <DVFS_INT_L3>;
				front_companion_video_capture_cam = <DVFS_CAM_L4>;
				front_companion_video_capture_mif = <DVFS_MIF_L4>;
				front_companion_video_capture_i2c = <0>;

				front_companion_video_whd_capture_int = <DVFS_INT_L3>;
				front_companion_video_whd_capture_cam = <DVFS_CAM_L4>;
				front_companion_video_whd_capture_mif = <DVFS_MIF_L4>;
				front_companion_video_whd_capture_i2c = <0>;

				rear_preview_fhd_int = <DVFS_INT_L4>;
				rear_preview_fhd_cam = <DVFS_CAM_L1>;
				rear_preview_fhd_mif = <DVFS_MIF_L4>;
				rear_preview_fhd_i2c = <0>;

				rear_preview_whd_int = <DVFS_INT_L4>;
				rear_preview_whd_cam = <DVFS_CAM_L1>;
				rear_preview_whd_mif = <DVFS_MIF_L4>;
				rear_preview_whd_i2c = <0>;

				rear_preview_uhd_int = <DVFS_INT_L1>;
				rear_preview_uhd_cam = <DVFS_CAM_L1>;
				rear_preview_uhd_mif = <DVFS_MIF_L4>;
				rear_preview_uhd_i2c = <0>;

				rear_capture_int = <DVFS_INT_L4>;
				rear_capture_cam = <DVFS_CAM_L1>;
				rear_capture_mif = <DVFS_MIF_L4>;
				rear_capture_i2c = <0>;

				rear_video_fhd_int = <DVFS_INT_L5>;
				rear_video_fhd_cam = <DVFS_CAM_L1>;
				rear_video_fhd_mif = <DVFS_MIF_L4>;
				rear_video_fhd_i2c = <0>;

				rear_video_whd_int = <DVFS_INT_L5>;
				rear_video_whd_cam = <DVFS_CAM_L1>;
				rear_video_whd_mif = <DVFS_MIF_L4>;
				rear_video_whd_i2c = <0>;

				rear_video_uhd_int = <DVFS_INT_L1>;
				rear_video_uhd_cam = <DVFS_CAM_L1>;
				rear_video_uhd_mif = <DVFS_MIF_L4>;
				rear_video_uhd_i2c = <0>;

				rear_video_fhd_capture_int = <DVFS_INT_L5>;
				rear_video_fhd_capture_cam = <DVFS_CAM_L1>;
				rear_video_fhd_capture_mif = <DVFS_MIF_L4>;
				rear_video_fhd_capture_i2c = <0>;

				rear_video_whd_capture_int = <DVFS_INT_L5>;
				rear_video_whd_capture_cam = <DVFS_CAM_L1>;
				rear_video_whd_capture_mif = <DVFS_MIF_L4>;
				rear_video_whd_capture_i2c = <0>;

				rear_video_uhd_capture_int = <DVFS_INT_L1>;
				rear_video_uhd_capture_cam = <DVFS_CAM_L1>;
				rear_video_uhd_capture_mif = <DVFS_MIF_L4>;
				rear_video_uhd_capture_i2c = <0>;

				dual_preview_int = <DVFS_INT_L2>;
				dual_preview_cam = <DVFS_CAM_L2>;
				dual_preview_mif = <DVFS_MIF_L4>;
				dual_preview_i2c = <0>;

				dual_capture_int = <DVFS_INT_L2>;
				dual_capture_cam = <DVFS_CAM_L2>;
				dual_capture_mif = <DVFS_MIF_L4>;
				dual_capture_i2c = <0>;

				dual_video_int = <DVFS_INT_L5>;
				dual_video_cam = <DVFS_CAM_L2>;
				dual_video_mif = <DVFS_MIF_L4>;
				dual_video_i2c = <0>;

				dual_video_capture_int = <DVFS_INT_L5>;
				dual_video_capture_cam = <DVFS_CAM_L2>;
				dual_video_capture_mif = <DVFS_MIF_L4>;
				dual_video_capture_i2c = <0>;

				preview_high_speed_fps_int = <DVFS_INT_L2>;
				preview_high_speed_fps_cam = <DVFS_CAM_L3>;
				preview_high_speed_fps_mif = <DVFS_MIF_L4>;
				preview_high_speed_fps_i2c = <0>;

				video_high_speed_60fps_int = <DVFS_INT_L2>;
				video_high_speed_60fps_cam = <DVFS_CAM_L1>;
				video_high_speed_60fps_mif = <DVFS_MIF_L4>;
				video_high_speed_60fps_i2c = <0>;

				video_high_speed_120fps_int = <DVFS_INT_L2>;
				video_high_speed_120fps_cam = <DVFS_CAM_L3>;
				video_high_speed_120fps_mif = <DVFS_MIF_L3>;
				video_high_speed_120fps_i2c = <0>;

				video_high_speed_240fps_int = <DVFS_INT_L1>;
				video_high_speed_240fps_cam = <DVFS_CAM_L3>;
				video_high_speed_240fps_mif = <DVFS_MIF_L1>;
				video_high_speed_240fps_i2c = <0>;

				max_int = <DVFS_INT_L0>;
				max_cam = <DVFS_CAM_L0>;
				max_mif = <DVFS_MIF_L1>;
				max_i2c = <0>;
			};
		};
	};


	pinctrl@13470000 {
		fimc_is_ois: fimc-is-ois {
			samsung,pins = "gpc2-5", "gpc2-4";
			samsung,pin-function = <1>;
			samsung,pin-pud = <0>;
			samsung,pin-drv = <0>;
		};
		fimc_is_ois_hsi2c_on: fimc-is-ois-hsi2c-on {
			samsung,pins = "gpb0-3", "gpb0-2";
			samsung,pin-function = <2>;
			samsung,pin-pud = <0>;
			samsung,pin-drv = <0>;
		};
		fimc_is_hsi2c_off: fimc-is-hsi2c-off {
			samsung,pins = "gpb0-3", "gpb0-2";
			samsung,pin-function = <0>;
			samsung,pin-pud = <0>;
			samsung,pin-drv = <3>;
		};
	};

	pcie1@157B0000 {
		status = "okay";
	};

	pinctrl@15690000{
		simslot_irq: simslot-irq {
			samsung,pins = "gpr3-3";
			samsung,pin-function = <0xf>;
			samsung,pin-pud = <0>;
			samsung,pin-drv = <0>;
		};

		sub_pmic_irq: sub-pmic-irq {
			samsung,pins ="gpr1-7";
			samsung,pin-function = <0>;
			samsung,pin-pud = <0>;
			samsung,pin-drv = <0>;
		};
	};

	bluetooth {
		compatible = "broadcom,bcm43455";
		gpios = <&gpf4 1 0	/*BT_EN*/
				&gpr1 3 0	/*BT_WAKE*/
				&gpa2 1 0	/*BT_HOST_WAKE*/ >;
		pinctrl-names = "default";
		pinctrl-0=<&bt_hostwake &bt_btwake &bt_en>;
		status = "okay";
	};

	pinctrl@15690000{
		bt_btwake: bt-btwake {
			samsung,pins = "gpr1-3";
			samsung,pin-function = <1>;
			samsung,pin-pud = <0>;
			samsung,pin-con-pdn = <3>;
			samsung,pin-pud-pdn = <0>;
		};
	};

	mipi-lli@10F24000 {
		status = "okay";
		memory-region = <&mipi_lli_reserved>;
		modem-name = "ss333";
		modems {
			ss300 {
				/* disable scrambler */
				scrambler = <0>;
				/* do not control automode by AP */
				automode = <0>;
			};

			ss303 {
				/* disable scrambler */
				scrambler = <0>;
				/* do not control automode by AP */
				automode = <0>;
			};

			ss333 {
				/* disable scrambler */
				scrambler = <0>;
				/* do not control automode by AP */
				automode = <0>;
			};

			xmm7260 {
				/* disable scrambler */
				scrambler = <0>;
				/* do not control automode by AP */
				automode = <0>;
			};
		};

		mphy {
			modem-name = "ss333";
			modems {
				ss300 {
					/* initial-gear is HS-G1 */
					init-gear = <2 1 1>;
					/* use shared reference clock for MPHY */
					shd-refclk = <1>;
				};

				ss303 {
					/* initial-gear is HS-G1 */
					init-gear = <2 1 1>;
					/* use shared reference clock for MPHY */
					shd-refclk = <1>;
				};

				ss333 {
					/* initial-gear is HS-G1 */
					init-gear = <2 1 1>;
					/* use shared reference clock for MPHY */
					shd-refclk = <1>;
				};

				xmm7260 {
					/* initial-gear is HS-G1 */
					init-gear = <2 1 1>;
					/* use shared reference clock for MPHY */
					shd-refclk = <1>;
				};
			};
		};
	};

	pinctrl@10580000 {
		cfg_wlanhostwake: cfg-wlanhostwake {
			samsung,pins = "gpa2-3";
			samsung,pin-function = <0>;
			samsung,pin-pud = <1>;
			samsung,pin-con-pdn = <2>;
			samsung,pin-pud-pdn = <0>;
		};
	};

	wlan {
		compatible = "samsung,brcm-wlan";
		gpios = <&gpf4 6 0x1 /* WLAN_EN */
				&gpa2 3 0x1 /* WLAN HOST WAKE GPIO_0 */>;
		pinctrl-names = "default";
		pinctrl-0 = <&cfg_wlanen &cfg_wlanhostwake>;
		status = "okay";
	};

	secgpio_dvs {
		compatible = "samsung,exynos7420-secgpio-dvs";
		status = "okay";
	};

	ufs@0x15570000 {
		ufs,pmd-attr-mode = "FAST";
		ufs,pmd-attr-lane = /bits/ 8 <2>;
		ufs,pmd-attr-gear = /bits/ 8 <2>;
		ufs,pmd-attr-hs-series = "HS_rate_b";
		ufs-opts-skip-connection-estab;
		ufs-rx-adv-fine-gran-sup_en = <0>;
		ufs-rx-min-activate-time-cap = <3>;
		ufs-rx-hibern8-time-cap = <2>;
		ufs-tx-hibern8-time-cap = <2>;

		vcc-supply = <&ufs_fixed_vcc>;
		vccq-supply = <&ufs_fixed_vccq>;
		vccq2-supply = <&ufs_fixed_vccq2>;
		vcc-fixed-regulator;
		vccq-fixed-regulator;
		vccq2-fixed-regulator;

		ufs-cap-clk-gating;
		ufs-cap-hibern8-with-clk-gating;
	};

	ufs_fixed_vcc: fixedregulator@0 {
		compatible = "regulator-fixed";
		regulator-name = "ufs-vcc";
		gpio = <&gph1 4 0>;
		enable-active-high;
		regulator-boot-on;
	};

	ufs_fixed_vccq: fixedregulator@1 {
		compatible = "regulator-fixed";
		regulator-name = "ufs-vccq";
		gpio = <&gph1 4 0>;
		enable-active-high;
		regulator-boot-on;
	};

	ufs_fixed_vccq2: fixedregulator@2 {
		 compatible = "regulator-fixed";
		 regulator-name = "ufs-vccq2";
		 gpio = <&gph1 4 0>;
		 enable-active-high;
		 startup-delay-us = <2000>;
		 endup-delay-us = <2000>;
		 regulator-boot-on;
	};

	sec_thermistor@0 {
		compatible = "samsung,sec-ap-thermistor";
		status = "okay";

		adc_array = <290 298 306 314 322 330 339 348 357 366
			375 386 397 408 419 430 447 464 481 498
			515 535 554 574 593 613 628 642 657 672
			686 709 733 756 780 803 832 861 891 920
			949 981 1013 1045 1077 1109 1144 1179 1215 1250
			1285 1323 1361 1398 1436 1474 1518 1562 1607 1651
			1695 1740 1786 1831 1877 1922 1969 2017 2064 2112
			2159 2207 2255 2302 2350 2398 2442 2486 2530 2574
			2618 2667 2716 2765 2814 2863 2904 2945 2986 3027
			3068 3107 3147 3186 3224 3262 3295 3328 3361 3394
			3427 3457 3487 3516 3546 3576 3600 3624 3648 3672
			3696>;
		temp_array = <900 890 880 870 860 850 840 830 820 810
			800 790 780 770 760 750 740 730 720 710
			700 690 680 670 660 650 640 630 620 610
			600 590 580 570 560 550 540 530 520 510
			500 490 480 470 460 450 440 430 420 410
			400 390 380 370 360 350 340 330 320 310
			300 290 280 270 260 250 240 230 220 210
			200 190 180 170 160 150 140 130 120 110
			100 90 80 70 60 50 40 30 20 10
			0 (-10) (-20) (-30) (-40) (-50) (-60) (-70) (-80) (-90)
			(-100)(-110)(-120)(-130)(-140)(-150)(-160)(-170)(-180)(-190)
			(-200)>;

		io-channels = <&exynos_adc 0>;
		io-channel-names = "adc-ap-temp";
		io-channel-ranges;
	};

	sec_thermistor@2 {
		compatible = "samsung,sec-pa-thermistor";
		status = "okay";

		adc_array = <215 224 234 243 253 262 271 281 290 300
			309 322 335 348 361 374 389 404 418 433
			448 465 482 499 516 533 553 573 594 614
			634 658 682 705 729 753 780 807 833 860
			887 918 948 979 1009 1040 1076 1112 1147 1183
			1219 1257 1295 1332 1370 1408 1448 1489 1529 1570
			1610 1653 1696 1739 1782 1825 1869 1913 1957 2001
			2045 2090 2134 2179 2223 2268 2310 2352 2395 2437
			2479 2520 2561 2601 2642 2683 2720 2757 2793 2830
			2867 2903 2939 2975 3011 3047 3077 3106 3136 3165
			3195 3221 3247 3274 3300 3326 3348 3370 3392 3414
			3436>;
		temp_array = <900 890 880 870 860 850 840 830 820 810
			800 790 780 770 760 750 740 730 720 710
			700 690 680 670 660 650 640 630 620 610
			600 590 580 570 560 550 540 530 520 510
			500 490 480 470 460 450 440 430 420 410
			400 390 380 370 360 350 340 330 320 310
			300 290 280 270 260 250 240 230 220 210
			200 190 180 170 160 150 140 130 120 110
			100 90 80 70 60 50 40 30 20 10
			0 (-10) (-20) (-30) (-40) (-50) (-60) (-70) (-80) (-90)
			(-100)(-110)(-120)(-130)(-140)(-150)(-160)(-170)(-180)(-190)
			(-200)>;

		io-channels = <&exynos_adc 2>;
		io-channel-names = "adc-pa-temp";
		io-channel-ranges;
	};

	argos {
		compatible = "samsung,argos";
		#address-cells = <1>;
		/*  The device number should be assigned for each device, e.g. "boot_device@1" and "boot_device@2".
		 * Duplicated number is not allowed. Please refer the below example. */

		/* Table Format should be
		 * <Throughput(Mbps) ARM_min ARM_max KFC_min KFC_max MIF INT Task IRQ HMP_boost>
		 * ARM_min : Big Core's minimum frequency lock. 0 means not set,
		 * ARM_max : Big Core's maximum frequency lock. 0 means not set,
		 * KFC_min : Little Core's minimum frequency lock. 0 means not set,
		 * KFC_max : Little Core's maximum frequency lock. 0 means not set,
		 * MIF : MIF frequency lock. 0 means not set,
		 * INT : INT frequency lock. 0 means not set,
		 * Task : 1 - Set task affinity lock.
		 *	0 - Not set or unlock,
		 *		Task affinity should be predefined driver's code.
		 * IRQ : 1 - Set irq affinity lock.
		 *       0 - Not set or unlock,
		 *		Task affinity should be predefined driver's code.
		 * HMP_boots : 1 - Increase hmp boosting count
		 *             0 - Decrease hmp boosting count
		 */
		boot_device@1 {
			net_boost,label="IPC";
			net_boost,node="rmnet0 rmnet1 rmnet2 rmnet3 rmnet4 rmnet5 rmnet6 rmnet7";
			net_boost,table_size = <2>;
			net_boost,table= <
				100 0 0 1100000 0 825000 100000 0 1 0
				130 0 0 1300000 0 825000 100000 0 1 0
				>;
		};
		/* Example
		boot_device@2 {
			net_boost,label="EMMC";
			net_boost,node="";
			net_boost,sysnode="/sys/class/mmc_host/mmc0/trans_count";
			net_boost,table_size = <1>;
			net_boost,table= <64 0 0 1300000 0 825000 400000 0 0>;
		};
		*/
		boot_device@2 {
			net_boost,label="UFS";
			net_boost,node="";
			net_boost,sysnode="/sys/class/scsi_host/host0/transferred_cnt";
			net_boost,table_size = <1>;
			net_boost,table= <64 0 0 1300000 0 1264000 400000 0 0 0>;
		};
		boot_device@3 {
			net_boost,label="P2P";
			net_boost,node="p2p-wlan0-0";
			net_boost,table_size = <2>;
			net_boost,table= <
				30 1200000 0 1200000 0 0 200000 0 0 0
				90 1700000 0 1200000 0 543000 267000 0 0 1
				>;
		};
		boot_device@4 {
			net_boost,label="WIFI";
			net_boost,node="wlan0";
			net_boost,table_size = <3>;
			net_boost,table= <
				20 1000000 0 800000 0 0 200000 0 0 0
				60 1500000 0 1200000 0 0 200000 0 0 0
				180 1896000 0 1500000 0 543000 267000 1 1 1
				>;
		};
		boot_device@5 {
			net_boost,label="CLAT";
			net_boost,node="clat clat4";
			net_boost,table_size = <3>;
			net_boost,table= <
				120 1400000 0 0 0 825000 0 0 0 0
				130 1500000 0 0 0 825000 0 0 0 0
				150 1600000 0 0 0 825000 0 0 0 0
				>;
		};

		boot_device@6 {
			net_boost,label="QIPC";
			net_boost,node="rmnet_data0 rmnet_data1 rmnet_data2 rmnet_data3 rmnet_data4 rmnet_data5 rmnet_data6 rmnet_data7";
			net_boost,table_size = <2>;
			net_boost,table= <
				10 0 0 1104000 0 825000 100000 0 1 0 /* 10Mbps little core 1.1G */
				100 0 0 1500000 0 825000 100000 0 1 0 /* 100Mbps little core 1.5G */
				>;
		};
	};

	input_booster {
		status = "okay";
		compatible = "input_booster";
		#address-cells = <1>;
		#size-cells = <0>;

		booster_key@1 {
			input_booster,label = "KEY";
			input_booster,type = <0>;	/* BOOSTER_DEVICE_KEY */

			input_booster,levels = <1>;

			/* Frequency table */
			/* for level	:	1_Head */
			input_booster,cpu_freqs = <1200000>;
			input_booster,hmp_boost = <1>;
			input_booster,kfc_freqs = <0>;
			input_booster,mif_freqs = <0>;
			input_booster,int_freqs = <0>;

			/* Time table */
			input_booster,head_times = <500>;
			input_booster,tail_times = <500>;
			input_booster,phase_times = <0>;
		};
		booster_key@2 {
			input_booster,label = "TOUCHKEY";
			input_booster,type = <1>;	/* BOOSTER_DEVICE_TOUCHKEY */

			input_booster,levels = <1>;

			/* Frequency table */
			/* for level	:	1_Head */
			input_booster,cpu_freqs = <1200000>;
			input_booster,hmp_boost = <1>;
			input_booster,kfc_freqs = <0>;
			input_booster,mif_freqs = <0>;
			input_booster,int_freqs = <0>;

			/* Time table */
			input_booster,head_times = <0>;
			input_booster,tail_times = <200>;
			input_booster,phase_times = <0>;
		};
		booster_key@3 {
			input_booster,label = "TOUCH";
			input_booster,type = <2>;	/* BOOSTER_DEVICE_TOUCH */

			input_booster,levels = <1 2 3>;

			/* Frequency table */
			/* for level	:	1_Head, 2_Head, 2_Tail */
			input_booster,cpu_freqs = <1200000 1200000 0>;
			input_booster,hmp_boost = <1 1 0>;
			input_booster,kfc_freqs = <800000 800000 1296000>;
			input_booster,mif_freqs = <0 0 0>;
			input_booster,int_freqs = <0 0 0>;

			/* Time table */
			input_booster,head_times = <130 130 0>;
			input_booster,tail_times = <0 0 500>;
			input_booster,phase_times = <0 0 0>;
		};
		booster_key@4 { // Input Booster +
			input_booster,label = "MULTITOUCH";
			input_booster,type = <3>;	/* BOOSTER_DEVICE_MULTITOUCH */

			input_booster,levels = <1 2>;

			/* Frequency table */
			/* for level	:	1_Head 2_Tail*/
			input_booster,cpu_freqs = <1200000 0>;
			input_booster,hmp_boost = <1 1>;
			input_booster,kfc_freqs = <800000 800000>;
			input_booster,mif_freqs = <0 0>;
			input_booster,int_freqs = <0 0>;

			/* Time table */
			input_booster,head_times = <1000 0>;
			input_booster,tail_times = <0 500>;
			input_booster,phase_times = <0 0>;
		};
		booster_key@5 {
			input_booster,label = "KEYBOARD";
			input_booster,type = <4>;	/* BOOSTER_DEVICE_KEYBOARD */

			input_booster,levels = <1 2>;

			/* Frequency table */
			/* for level	:	1_Head 2_Tail*/
			input_booster,cpu_freqs = <1200000 1200000>;
			input_booster,hmp_boost = <1 1>;
			input_booster,kfc_freqs = <800000 800000>;
			input_booster,mif_freqs = <0 0>;
			input_booster,int_freqs = <0 0>;

			/* Time table */
			input_booster,head_times = <130 130>;
			input_booster,tail_times = <0 0>;
			input_booster,phase_times = <0 0>;
		};
		booster_key@6 {
			input_booster,label = "MOUSE";
			input_booster,type = <5>;	/* BOOSTER_DEVICE_MOUSE */

			input_booster,levels = <1 2>;

			/* Frequency table */
			/* for level	:	1_Head 2_Tail*/
			input_booster,cpu_freqs = <1200000 0>;
			input_booster,hmp_boost = <1 0>;
			input_booster,kfc_freqs = <800000 1200000>;
			input_booster,mif_freqs = <0 0>;
			input_booster,int_freqs = <0 0>;

			/* Time table */
			input_booster,head_times = <130 0>;
			input_booster,tail_times = <0 500>;
			input_booster,phase_times = <0 0>;
		};
		booster_key@7 {
			input_booster,label = "MOUSE WHEEL";
			input_booster,type = <6>;	/* BOOSTER_DEVICE_MOUSE */

			input_booster,levels = <1 2>;

			/* Frequency table */
			/* for level	:	1_Head 2_Tail*/
			input_booster,cpu_freqs = <1200000 0>;
			input_booster,hmp_boost = <1 0>;
			input_booster,kfc_freqs = <800000 0>;
			input_booster,mif_freqs = <0 0>;
			input_booster,int_freqs = <0 0>;

			/* Time table */
			input_booster,head_times = <130 0>;
			input_booster,tail_times = <0 0>;
			input_booster,phase_times = <0 0>;
		};
		booster_key@8 {
			input_booster,label = "PEN HOVER";
			input_booster,type = <7>;	/* BOOSTER_DEVICE_MOUSE */

			input_booster,levels = <1 2>;

			/* Frequency table */
			/* for level	:	1_Head 2_Tail*/
			input_booster,cpu_freqs = <1200000 0>;
			input_booster,hmp_boost = <1 0>;
			input_booster,kfc_freqs = <800000 1296000>;
			input_booster,mif_freqs = <0 0>;
			input_booster,int_freqs = <0 0>;

			/* Time table */
			input_booster,head_times = <130 0>;
			input_booster,tail_times = <0 500>;
			input_booster,phase_times = <0 0>;
		}; // Input Booster -
		/* If you need to add new key type, add it this position */
	};

	simslot_count {
		status = "disabled";
		compatible = "simslot_count";
		pinctrl-names = "default";
		pinctrl-0 = <&simslot_irq>;
		gpios = <&gpr3 3 0>;
	};
};
